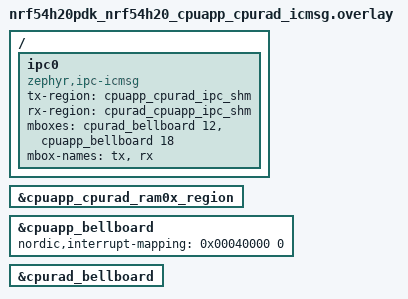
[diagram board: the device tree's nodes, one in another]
/*
 * Copyright (c) 2024 Nordic Semiconductor ASA
 * SPDX-License-Identifier: LicenseRef-Nordic-5-Clause
 */

/ {
	ipc0: ipc0 {
		compatible = "zephyr,ipc-icmsg";
		tx-region = <&cpuapp_cpurad_ipc_shm>;
		rx-region = <&cpurad_cpuapp_ipc_shm>;
		mboxes = <&cpurad_bellboard 12>,
			 <&cpuapp_bellboard 18>;
		mbox-names = "tx", "rx";
		status = "okay";
	};
};

&cpuapp_cpurad_ram0x_region {
	status = "okay";
};

&cpuapp_bellboard {
	status = "okay";
	nordic,interrupt-mapping = <0x00040000 0>;
};

&cpurad_bellboard {
	status = "okay";
};
